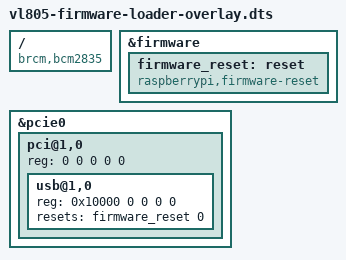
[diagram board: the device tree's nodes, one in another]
/dts-v1/;
/plugin/;

/{
	compatible = "brcm,bcm2835";

	fragment@0 {
		target = <&firmware>;
		__overlay__ {
			firmware_reset: reset {
				compatible = "raspberrypi,firmware-reset";
				#reset-cells = <1>;
			};
		};
	};

	fragment@1 {
		target = <&pcie0>;
		__overlay__ {
			pci@1,0 {
				#address-cells = <3>;
				#size-cells = <2>;
				ranges;

				reg = <0 0 0 0 0>;

				usb@1,0 {
					reg = <0x10000 0 0 0 0>;
					resets = <&firmware_reset 0>;
				};
			};
		};
	};
};

